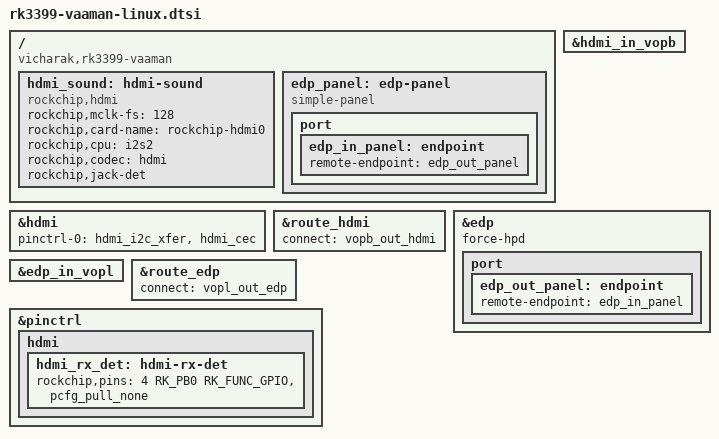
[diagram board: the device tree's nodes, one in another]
// SPDX-License-Identifier: (GPL-2.0+ OR MIT)
/*
 * Copyright (C) 2023 Vicharak India
 */

#include "rk3399-vaaman.dtsi"
#include "rk3399-linux.dtsi"

/ {
	compatible = "vicharak,rk3399-vaaman", "rockchip,rk3399";

	/delete-node/ chosen;

	// HDMI Sound: {{{
	hdmi_sound: hdmi-sound {
		compatible = "rockchip,hdmi";
		rockchip,mclk-fs = <128>;
		rockchip,card-name = "rockchip-hdmi0";
		rockchip,cpu = <&i2s2>;
		rockchip,codec = <&hdmi>;
		rockchip,jack-det;
		status = "okay";
	};
	// End of HDMI Sound }}}

	// EDP Panel: {{{
	edp_panel: edp-panel {
		compatible = "simple-panel";
		status = "okay";

		port {
			edp_in_panel: endpoint {
				remote-endpoint = <&edp_out_panel>;
			};
		};
	};
	// End of EDP Panel }}}
};

// HDMI: {{{
&hdmi {
	pinctrl-names = "default";
	pinctrl-0 = <&hdmi_i2c_xfer>, <&hdmi_cec>;
	#address-cells = <1>;
	#size-cells = <0>;
	#sound-dai-cells = <0>;
	status = "okay";
};

&hdmi_in_vopb {
	status = "okay";
};

&route_hdmi {
	connect = <&vopb_out_hdmi>;
	status = "okay";
};

&hdmi_sound {
	status = "okay";
};
// End of HDMI }}}

// EDP: {{{
&edp {
	status = "okay";
	force-hpd;

	port {
		edp_out_panel: endpoint {
			remote-endpoint = <&edp_in_panel>;
		};
	};
};

&edp_in_vopl {
	status = "okay";
};

&route_edp {
	connect = <&vopl_out_edp>;
	status = "okay";
};
// End of EDP }}}

&pinctrl {
	// HDMI: {{{
	hdmi {
		hdmi_rx_det: hdmi-rx-det {
			rockchip,pins =
				<4 RK_PB0 RK_FUNC_GPIO &pcfg_pull_none>;
		};
	};
	// Endi of HDMI }}}
};
